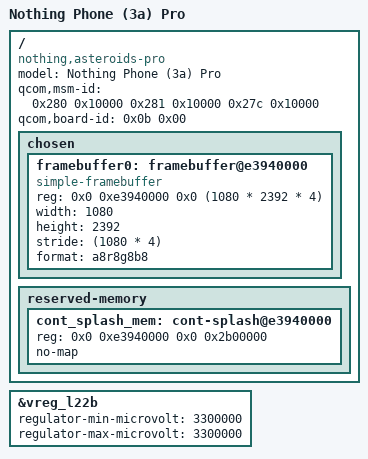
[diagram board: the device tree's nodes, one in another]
// SPDX-License-Identifier: BSD-3-Clause
/*
 * Nothing Phone (3a) Pro (A059P): experimental, not boot-tested.
 * The inherited Phone (3a) wiring has not been verified on the Pro.
 */

#include "milos-nothing-asteroids.dts"

/ {
	model = "Nothing Phone (3a) Pro";
	compatible = "nothing,asteroids-pro", "nothing,asteroids", "qcom,milos";
	qcom,msm-id = <0x280 0x10000 0x281 0x10000 0x27c 0x10000>;
	qcom,board-id = <0x0b 0x00>;

	chosen {
		#address-cells = <2>;
		#size-cells = <2>;
		ranges;

		framebuffer0: framebuffer@e3940000 {
			compatible = "simple-framebuffer";
			reg = <0x0 0xe3940000 0x0 (1080 * 2392 * 4)>;
			width = <1080>;
			height = <2392>;
			stride = <(1080 * 4)>;
			format = "a8r8g8b8";
		};
	};

	reserved-memory {
		cont_splash_mem: cont-splash@e3940000 {
			reg = <0x0 0xe3940000 0x0 0x2b00000>;
			no-map;
		};
	};
};

/* PM7550 L22 is specified as 3.3 V in the archived Pro stock FDT. */
&vreg_l22b {
	regulator-min-microvolt = <3300000>;
	regulator-max-microvolt = <3300000>;
};
